# STM32U3C5xx register map
File version: 1.0
Registers are 32-bit, read-write, reset 0x0 unless marked. A register's access mark holds for its fields unless they carry their own. Offsets are from the block's base; [hi:lo] are bit positions; {n}, {i} and the like mark numbered series.

## FLASH — FLASH Registers
Base 0x40022000
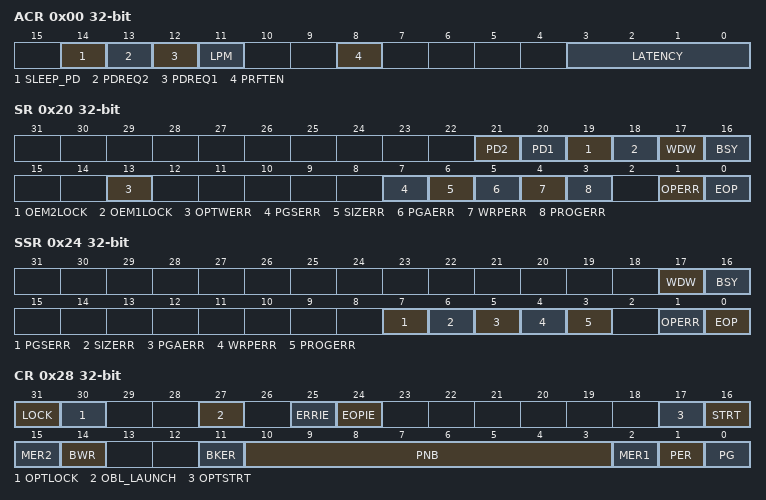
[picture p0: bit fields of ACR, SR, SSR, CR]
0x00 ACR — FLASH access control register
  [14] SLEEP_PD — Flash power-down mode during sleep
  [13] PDREQ2 — Bank 2 power-down mode request
  [12] PDREQ1 — Bank 1 power-down mode request
  [11] LPM — Low-Power read mode
  [8] PRFTEN — Prefetch enable
  [3:0] LATENCY
    0=FLASH zero wait state; 1=FLASH one wait state; 2=FLASH two wait states; 3=FLASH three wait states; 4=FLASH four wait states; 5=FLASH five wait states; 6=FLASH six wait state; 7=FLASH Seven wait states; 8=FLASH Eight wait states; 9=FLASH nine wait states; 10=FLASH ten wait states; 11=FLASH eleven wait states; 12=FLASH twelve wait states; 13=FLASH thirteen wait states; 14=FLASH fourteen wait states; 15=FLASH fifteen wait states
0x08 KEYR — FLASH non-secure key register
  [31:0] KEY — Flash non-secure key
0x0C SKEYR — FLASH secure key register
  [31:0] KEY — Flash secure key
0x10 OPTKEYR — FLASH option key register
  [31:0] KEY — Option byte key
0x18 PDKEY1R — FLASH bank 1 power-down key register
  [31:0] KEY1 — Bank 1 power-down key
0x1C PDKEY2R — FLASH bank 2 power-down key register
  [31:0] KEY2 — Bank 2 power-down key
0x20 SR — FLASH non-secure status register
  [21] PD2 — Bank 2 in power-down mode
  [20] PD1 — Bank 1 in power-down mode
  [19] OEM2LOCK
  [18] OEM1LOCK
  [17] WDW — Non-secure wait data to write
  [16] BSY — Non-secure busy
  [13] OPTWERR — Option write error
  [7] PGSERR — Non-secure programming sequence error
  [6] SIZERR — Non-secure size error
  [5] PGAERR — Non-secure programming alignment error
  [4] WRPERR — Non-secure write protection error
  [3] PROGERR — Non-secure programming error
  [1] OPERR — Non-secure operation error
  [0] EOP — Non-secure end of operation
0x24 SSR — FLASH secure status register
  [17] WDW — Secure wait data to write
  [16] BSY — Secure busy
  [7] PGSERR — Secure programming sequence error
  [6] SIZERR — Secure size error
  [5] PGAERR — Secure programming alignment error
  [4] WRPERR — Secure write protection error
  [3] PROGERR — Secure programming error
  [1] OPERR — Secure operation error
  [0] EOP — Secure end of operation
0x28 CR — FLASH non-secure control register
  [31] LOCK — Non-secure Lock
  [30] OPTLOCK — Option Lock
  [27] OBL_LAUNCH — Force the option byte loading
  [25] ERRIE — Non-secure error interrupt enable
  [24] EOPIE — Non-secure end of operation interrupt enable
  [17] OPTSTRT — Option modification Start
  [16] STRT — Non-secure start
  [15] MER2 — Non-secure bank 2 mass erase
  [14] BWR — Non-secure burst write programming mode
  [11] BKER — Non-secure bank selection for page erase
  [10:3] PNB — Non-secure page number selection
  [2] MER1 — Non-secure bank 1 mass erase
  [1] PER — Non-secure page erase
  [0] PG — Non-secure programming
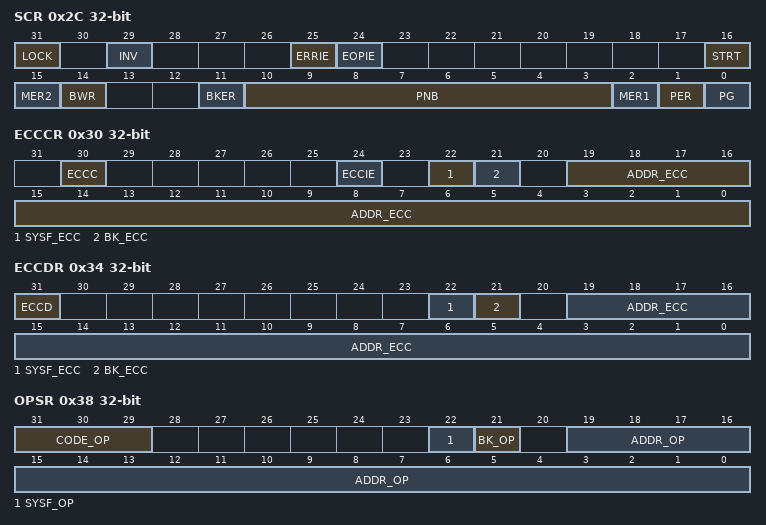
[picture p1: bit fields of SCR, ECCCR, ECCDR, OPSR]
0x2C SCR — FLASH secure control register
  [31] LOCK — Secure lock
  [29] INV — Flash security state invert
  [25] ERRIE — Secure error interrupt enable
  [24] EOPIE — Secure end of operation interrupt enable
  [16] STRT — Secure start
  [15] MER2 — Secure bank 2 mass erase
  [14] BWR — Secure burst write programming mode
  [11] BKER — Secure bank selection for page erase
  [10:3] PNB — Secure page number selection
  [2] MER1 — Secure bank 1 mass erase
  [1] PER — Secure page erase
  [0] PG — Secure programming
0x30 ECCCR — FLASH ECC correction register
  [30] ECCC — ECC correction
  [24] ECCIE — ECC correction interrupt enable
  [22] SYSF_ECC — System Flash ECC fail
  [21] BK_ECC — ECC fail bank
  [19:0] ADDR_ECC — ECC fail address
0x34 ECCDR — FLASH ECC detection register
  [31] ECCD — ECC detection
  [22] SYSF_ECC — System Flash ECC fail
  [21] BK_ECC — ECC fail bank
  [19:0] ADDR_ECC — ECC fail address
0x38 OPSR — FLASH OPSR register
  [31:29] CODE_OP — Flash operation code
  [22] SYSF_OP — Operation in System Flash interrupted
  [21] BK_OP — Interrupted operation bank
  [19:0] ADDR_OP — Interrupted operation address
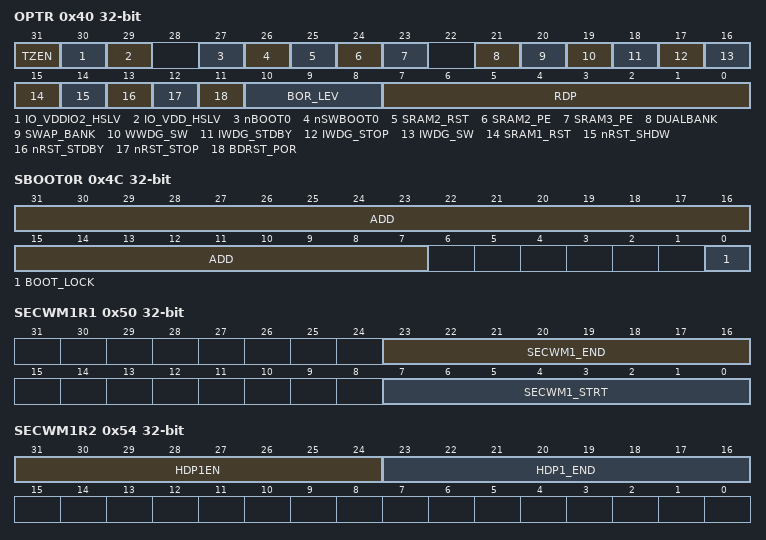
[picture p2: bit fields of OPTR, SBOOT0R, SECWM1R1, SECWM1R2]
0x40 OPTR — FLASH option control register
  [31] TZEN — Global TrustZone security enable
  [30] IO_VDDIO2_HSLV — High speed IO at low VDDIO2 voltage configuration bit
  [29] IO_VDD_HSLV — High speed IO at low VDD voltage configuration bit
  [27] nBOOT0 — nBOOT0 option bit
  [26] nSWBOOT0 — Software BOOT0
  [25] SRAM2_RST — SRAM2 erase when system reset
  [24] SRAM2_PE — SRAM2 parity check enable
  [23] SRAM3_PE — SRAM3 parity check enable
  [21] DUALBANK — Dual-bank on 1Mbyte Flash memory devices
  [20] SWAP_BANK — Swap banks
  [19] WWDG_SW — Window watchdog selection
  [18] IWDG_STDBY — Independent watchdog counter freeze in standby mode
  [17] IWDG_STOP — Independent watchdog counter freeze in stop mode
  [16] IWDG_SW — Independent watchdog selection
  [15] SRAM1_RST — SRAM1 erase upon system reset
  [14] nRST_SHDW — Reset generation in shutdown mode
  [13] nRST_STDBY — Reset generation in standby mode
  [12] nRST_STOP — Reset generation in stop mode
  [11] BDRST_POR — Backup domain reset with power on reset
  [10:8] BOR_LEV — BOR reset level
  [7:0] RDP — Readout protection level
0x44 BOOT0R — FLASH non-secure boot address 0 register
  [31:7] ADD — Non-secure boot base address 0
0x48 BOOT1R — FLASH non-secure boot address 1 register
  [31:7] ADD — Non-secure boot base address 1
0x4C SBOOT0R — FLASH secure boot address 0 register
  [31:7] ADD — Secure boot base address 0
  [0] BOOT_LOCK
0x50 SECWM1R1 — FLASH secure watermark1 register 1
  [23:16] SECWM1_END — End page of first secure area
  [7:0] SECWM1_STRT — Start page of first secure area
0x54 SECWM1R2 — FLASH secure watermark1 register 2
  [31:24] HDP1EN — Hide protection first area enable
  [23:16] HDP1_END — End page of first hide protection area
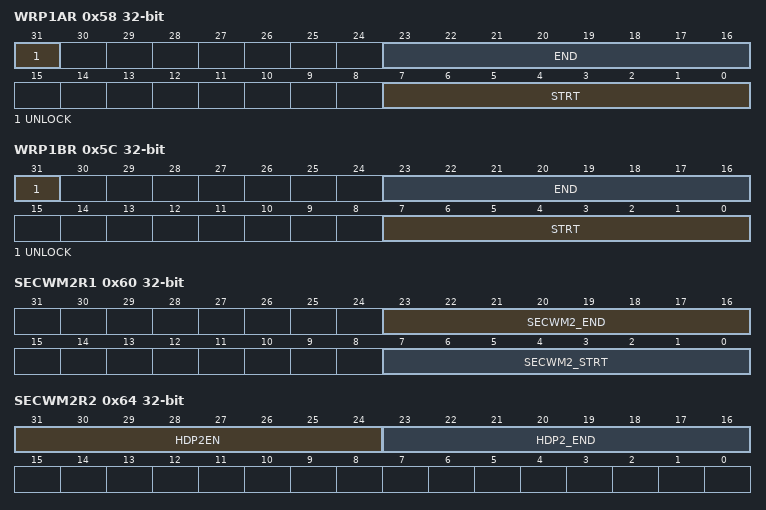
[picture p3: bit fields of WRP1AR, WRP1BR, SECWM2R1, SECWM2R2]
0x58 WRP1AR — FLASH WRP1 area A address register
  [31] UNLOCK — Bank 1 WRP first area A unlock
  [23:16] END — Bank 1 WRP first area A end page
  [7:0] STRT — Bank 1 WRP first area A start page
0x5C WRP1BR — FLASH WRP1 area B address register
  [31] UNLOCK — Bank 1 WRP second area B unlock
  [23:16] END — Bank 1 WRP second area B end page
  [7:0] STRT — Bank 1 WRP second area B start page
0x60 SECWM2R1 — FLASH secure watermark2 register 1
  [23:16] SECWM2_END — End page of second secure area
  [7:0] SECWM2_STRT — Start page of second secure area
0x64 SECWM2R2 — FLASH secure watermark2 register 2
  [31:24] HDP2EN — Hide protection second area enable
  [23:16] HDP2_END — End page of hide protection second area
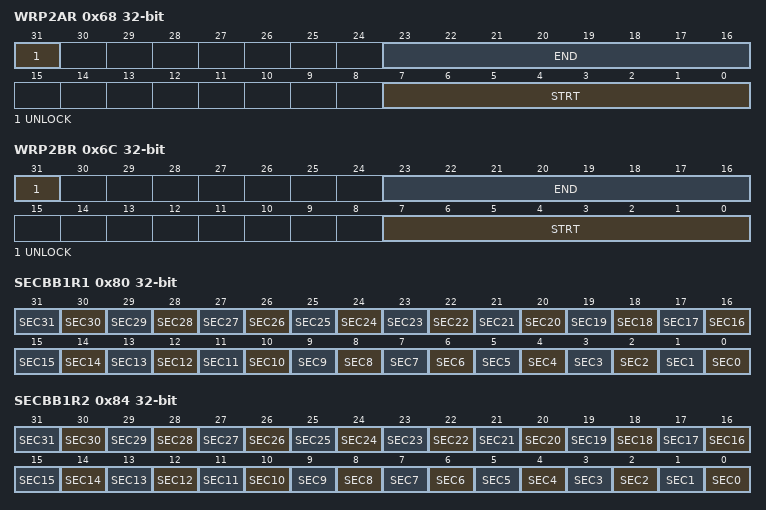
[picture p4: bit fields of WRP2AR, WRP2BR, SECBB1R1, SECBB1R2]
0x68 WRP2AR — FLASH WRP2 area A address register
  [31] UNLOCK — Bank 2 WPR first area A unlock
  [23:16] END — Bank 2 WPR first area A end page
  [7:0] STRT — Bank 2 WPR first area A start page
0x6C WRP2BR — FLASH WRP2 area B address register
  [31] UNLOCK — Bank 2 WPR second area B unlock
  [23:16] END — Bank 2 WPR second area B end page
  [7:0] STRT — Bank 2 WPR second area B start page
0x80 SECBB1R1 — FLASH secure block-based bank 1 register 1
  [n] SEC{n} (n=0..31) — Page {n} in bank 1 block-based secure
0x84 SECBB1R2 — FLASH secure block-based bank 1 register 2
  [n] SEC{n} (n=0..31) — Page {n+32} in bank 1 block-based secure
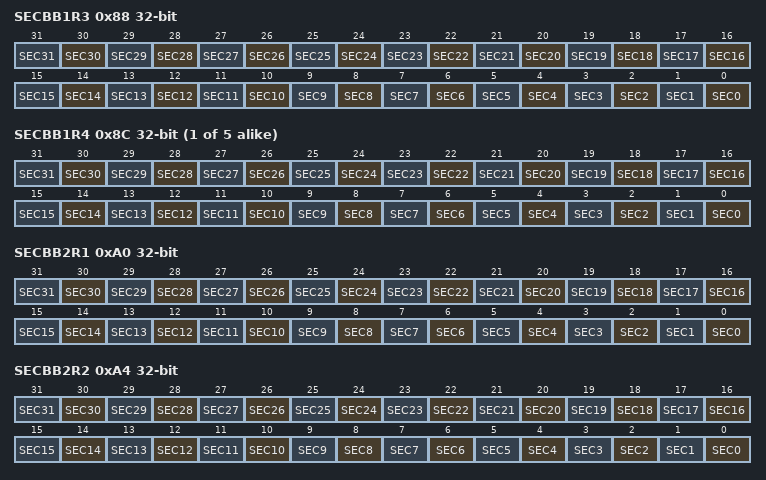
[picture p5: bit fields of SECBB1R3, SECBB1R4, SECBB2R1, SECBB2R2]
0x88 SECBB1R3 — FLASH secure block-based bank 1 register 3
  [n] SEC{n} (n=0..31) — Page {n+64} in bank 1 block-based secure
{0x7C+4i} SECBB1R{i} (i=4..8) — FLASH secure block-based bank 1 register {i}
  [n] SEC{n} (n=0..31) — Page {n+96} in bank 1 block-based secure
0xA0 SECBB2R1 — FLASH secure block-based bank 2 register 1
  [n] SEC{n} (n=0..31) — Page {n} in bank 2 block-based secure
0xA4 SECBB2R2 — FLASH secure block-based bank 2 register 2
  [n] SEC{n} (n=0..31) — Page {n+32} in bank 2 block-based secure
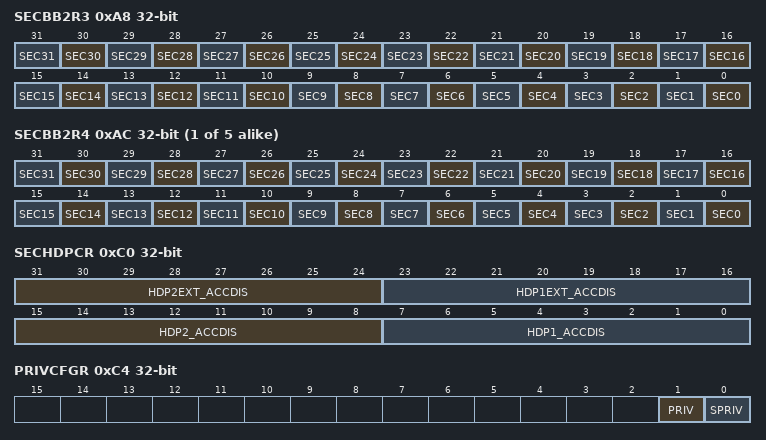
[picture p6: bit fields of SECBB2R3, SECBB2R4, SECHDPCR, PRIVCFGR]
0xA8 SECBB2R3 — FLASH secure block-based bank 2 register 3
  [n] SEC{n} (n=0..31) — Page {n+64} in bank 2 block-based secure
{0x9C+4i} SECBB2R{i} (i=4..8) — FLASH secure block-based bank 2 register {i}
  [n] SEC{n} (n=0..31) — Page {n+96} in bank 2 block-based secure
0xC0 SECHDPCR — FLASH secure HDP control register
  [31:24] HDP2EXT_ACCDIS — HDP2 extension area access disable
  [23:16] HDP1EXT_ACCDIS — HDP1 extension area access disable
  [15:8] HDP2_ACCDIS — HDP2 area access disable
  [7:0] HDP1_ACCDIS — HDP1 area access disable
0xC4 PRIVCFGR — FLASH privilege configuration register
  [1] PRIV — Privilege protection for non-secure registers
  [0] SPRIV — Privilege protection for secure registers
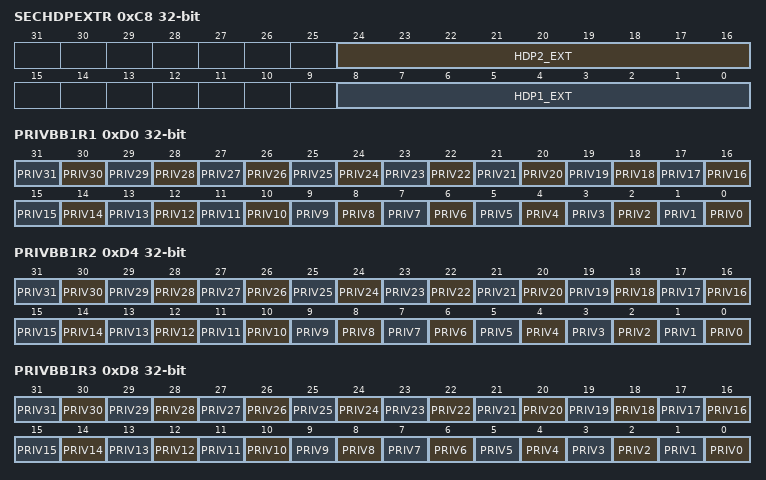
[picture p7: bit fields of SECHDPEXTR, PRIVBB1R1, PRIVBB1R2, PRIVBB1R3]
0xC8 SECHDPEXTR — FLASH HDP extension register
  [24:16] HDP2_EXT — HDP area extension in 4Kbytes pages in bank 2
  [8:0] HDP1_EXT — HDP area extension in 4Kbytes pages in bank 1
0xD0 PRIVBB1R1 — FLASH privilege block-based bank 1 register 1
  [n] PRIV{n} (n=0..31) — Page {n} in bank 1 block-based privilege
0xD4 PRIVBB1R2 — FLASH privilege block-based bank 1 register 2
  [n] PRIV{n} (n=0..31) — Page {n+32} in bank 1 block-based privilege
0xD8 PRIVBB1R3 — FLASH privilege block-based bank 1 register 3
  [n] PRIV{n} (n=0..31) — Page {n+64} in bank 1 block-based privilege
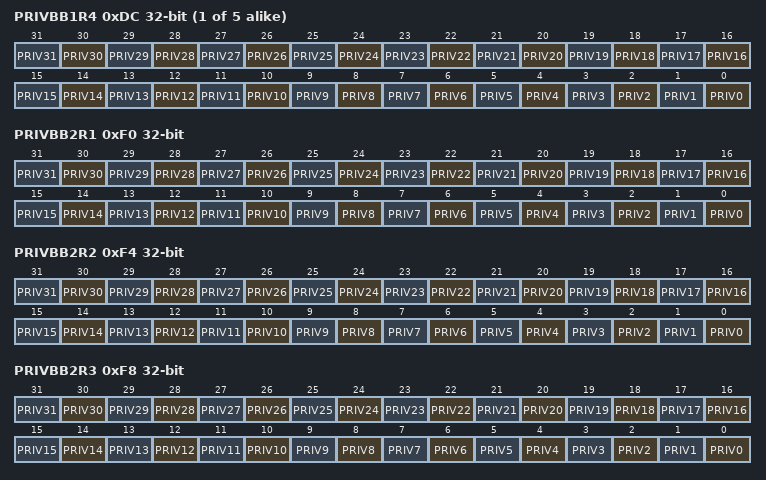
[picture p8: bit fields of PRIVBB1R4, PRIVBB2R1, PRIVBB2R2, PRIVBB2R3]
{0xCC+4i} PRIVBB1R{i} (i=4..8) — FLASH privilege block-based bank 1 register {i}
  [n] PRIV{n} (n=0..31) — Page {n+96} in bank 1 block-based privilege
0xF0 PRIVBB2R1 — FLASH privilege block-based bank 2 register 1
  [n] PRIV{n} (n=0..31) — Page {n} in bank 2 block-based privilege
0xF4 PRIVBB2R2 — FLASH privilege block-based bank 2 register 2
  [n] PRIV{n} (n=0..31) — Page {n+32} in bank 2 block-based privilege
0xF8 PRIVBB2R3 — FLASH privilege block-based bank 2 register 3
  [n] PRIV{n} (n=0..31) — Page {n+64} in bank 2 block-based privilege
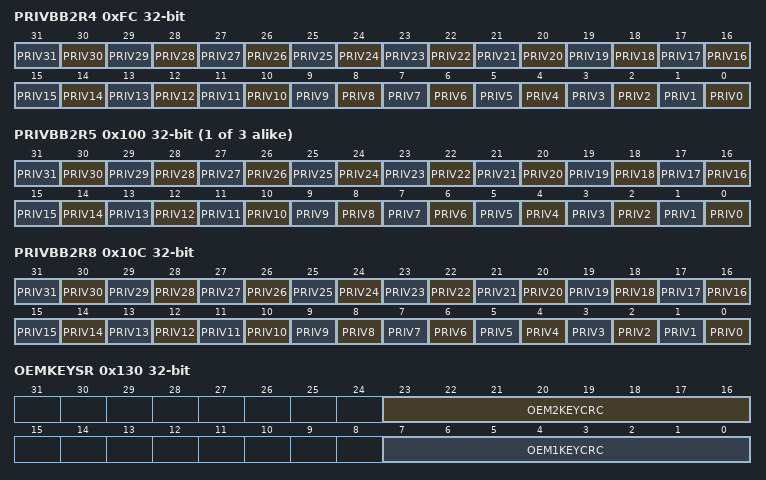
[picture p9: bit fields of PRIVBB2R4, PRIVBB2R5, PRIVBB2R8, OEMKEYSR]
0xFC PRIVBB2R4 — FLASH privilege block-based bank 2 register 4
  [n] PRIV{n} (n=0..31) — Page {n+96} in bank 2 block-based privilege
{0xEC+4i} PRIVBB2R{i} (i=5..7) — FLASH privilege block-based bank 2 register {i}
  [n] PRIV{n} (n=0..31) — Page {n} in bank 2 block-based privilege
0x10C PRIVBB2R8 — FLASH privilege block-based bank 2 register 8
  [n] PRIV{n} (n=0..31) — Page {n+96} in bank 2 block-based privilege
{0x10C+4i} OEM1KEYR{i} (i=1..4) — FLASH OEM1 key register {i}
  [31:0] OEM1KEY — OEM1 [{32i-1}:{32i-32}] bytes key
{0x11C+4i} OEM2KEYR{i} (i=1..4) — FLASH OEM2 key register {i}
  [31:0] OEM2KEY — OEM2 [{32i-1}:{32i-32}] bytes key
0x130 OEMKEYSR — FLASH OEM key status register
  [23:16] OEM2KEYCRC — 8-bits OEMKEY2 CRC
  [7:0] OEM1KEYCRC — 8-bits OEMKEY1 CRC
